AUTOSAR XML (schema 4-2-2)
package /Sbc
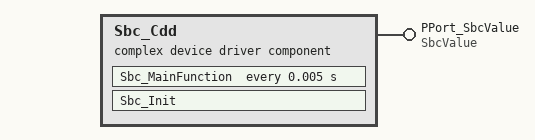
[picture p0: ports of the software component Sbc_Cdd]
  complex device driver sw component type Sbc_Cdd
    provide port PPort_SbcValue: provided-interface=SbcValue
    behavior SwcInternalBehavior
      timing event TE_Sbc_MainFunction_10ms: start-on-event=Sbc_MainFunction, period=0.005
      runnable Sbc_MainFunction
        data-send-points:
          access DSP_KL15WakeupState_flg_0: accessed-variable=PPort_SbcValue.KL15WakeupState_flg
          access DSP_BMULastPwrDownState_0: accessed-variable=PPort_SbcValue.BMULastPwrDownState
      runnable Sbc_Init
